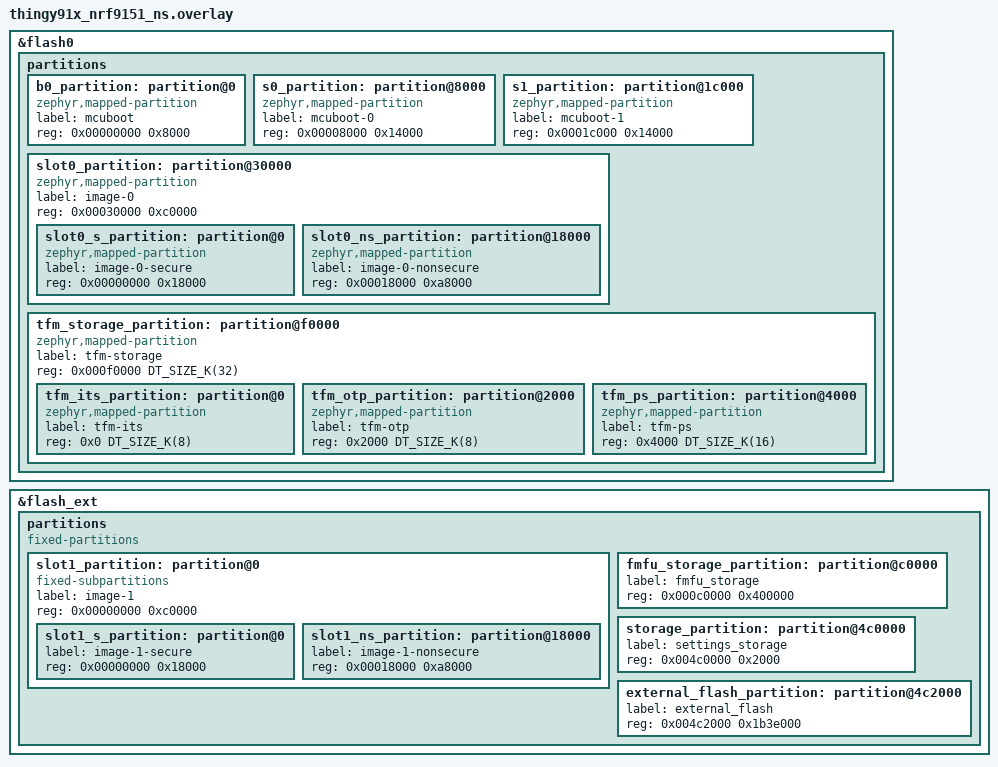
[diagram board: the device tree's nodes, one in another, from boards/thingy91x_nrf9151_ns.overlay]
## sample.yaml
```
sample:
  description: Cellular IoT Fundamentals Course by Nordic Developer Academy (https://academy.nordicsemi.com/)
  name: Cellular IoT Fundamentals Course - Lesson 5 Exercise 1 Solution
  
common: 
    sysbuild: true
    build_only: true
    integration_platforms: 
      - nrf9151dk/nrf9151/ns
      - nrf9161dk/nrf9161/ns
      - nrf9160dk/nrf9160/ns
      - thingy91x/nrf9151/ns
      - thingy91/nrf9160/ns
    platform_allow: 
      - nrf9151dk/nrf9151/ns
      - nrf9161dk/nrf9161/ns
      - nrf9160dk/nrf9160/ns
      - thingy91x/nrf9151/ns
      - thingy91/nrf9160/ns

tests:
  cell_fund.l5.e1_sol: {}
```

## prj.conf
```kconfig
#
# Copyright (c) 2019 Nordic Semiconductor ASA
#
# SPDX-License-Identifier: LicenseRef-Nordic-5-Clause
#

# Logging
CONFIG_LOG=y

# Button and LED support
CONFIG_DK_LIBRARY=y

# Newlib
CONFIG_NEWLIB_LIBC=y

# Network
CONFIG_NETWORKING=y
CONFIG_NET_NATIVE=n
CONFIG_NET_SOCKETS=y
CONFIG_NET_SOCKETS_OFFLOAD=y

# Memory
CONFIG_HEAP_MEM_POOL_SIZE=4096
CONFIG_MAIN_STACK_SIZE=4096

# Modem library
CONFIG_NRF_MODEM_LIB=y

# LTE link control
CONFIG_LTE_LINK_CONTROL=y
CONFIG_LTE_NETWORK_MODE_LTE_M_NBIOT=y

# CoAP
# STEP 2.1 - Enable the CoAP library
CONFIG_COAP=y

# STEP 3.1 - Configure the CoAP server hostname
CONFIG_COAP_SERVER_HOSTNAME="californium.eclipseprojects.io"

# STEP 3.2 - Configure the CoAP resource for TX and RX communication
CONFIG_COAP_TX_RESOURCE="large-update"
CONFIG_COAP_RX_RESOURCE="validate"

CONFIG_TFM_PROFILE_TYPE_SMALL=y
CONFIG_TFM_LOG_LEVEL_SILENCE=y
```

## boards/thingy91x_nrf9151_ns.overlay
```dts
/delete-node/ &slot0_partition;
/delete-node/ &slot1_partition;
/delete-node/ &s0_partition;
/delete-node/ &s1_partition;
/delete-node/ &storage_partition;
/delete-node/ &external_flash_partition;
/delete-node/ &fmfu_storage_partition;

&flash0 {
	/*
	 * 0x0000_0000  MCUboot (B0/NSIB)            ( 32 kB)
	 * 0x0000_8000  Primary updatable MCUboot    ( 80 kB)
	 * 0x0001_c000  Secondary updatable MCUboot  ( 80 kB)
	 * 0x0003_0000  Primary image area           (768 kB)
	 *   0x0003_0000  Primary secure image       ( 96 kB)
	 *   0x0004_8000  Primary non-secure image   (672 kB)
	 * 0x000f_0000  TF-M storage area            ( 32 kB)
	 *   0x000f_0000  TF-M Internal Trusted Stg  (  8 kB)
	 *   0x000f_2000  TF-M OTP / NV counters     (  8 kB)
	 *   0x000f_4000  TF-M Protected Storage     ( 16 kB)
	 * 0x000f_8000  Free                         ( 32 kB)
	 */
	partitions {
		ranges;
		#address-cells = <1>;
		#size-cells = <1>;

		b0_partition: partition@0 {
			compatible = "zephyr,mapped-partition";
			label = "mcuboot";
			reg = <0x00000000 0x8000>;
		};

		s0_partition: partition@8000 {
			compatible = "zephyr,mapped-partition";
			label = "mcuboot-0";
			reg = <0x00008000 0x14000>;
		};

		s1_partition: partition@1c000 {
			compatible = "zephyr,mapped-partition";
			label = "mcuboot-1";
			reg = <0x0001c000 0x14000>;
		};

		slot0_partition: partition@30000 {
			compatible = "zephyr,mapped-partition";
			label = "image-0";
			reg = <0x00030000 0xc0000>;
			ranges = <0x0 0x00030000 0xc0000>;
			#address-cells = <1>;
			#size-cells = <1>;

			slot0_s_partition: partition@0 {
				compatible = "zephyr,mapped-partition";
				label = "image-0-secure";
				reg = <0x00000000 0x18000>;
			};

			slot0_ns_partition: partition@18000 {
				compatible = "zephyr,mapped-partition";
				label = "image-0-nonsecure";
				reg = <0x00018000 0xa8000>;
			};
		};

		tfm_storage_partition: partition@f0000 {
			compatible = "zephyr,mapped-partition";
			label = "tfm-storage";
			reg = <0x000f0000 DT_SIZE_K(32)>;
			ranges = <0x0 0x000f0000 DT_SIZE_K(32)>;
			#address-cells = <1>;
			#size-cells = <1>;

			tfm_its_partition: partition@0 {
				compatible = "zephyr,mapped-partition";
				label = "tfm-its";
				reg = <0x0 DT_SIZE_K(8)>;
			};

			tfm_otp_partition: partition@2000 {
				compatible = "zephyr,mapped-partition";
				label = "tfm-otp";
				reg = <0x2000 DT_SIZE_K(8)>;
			};

			tfm_ps_partition: partition@4000 {
				compatible = "zephyr,mapped-partition";
				label = "tfm-ps";
				reg = <0x4000 DT_SIZE_K(16)>;
			};
		};
	};
};

&flash_ext {
	/*
	 * 0x0000_0000  Secondary image area          (  768 kB)
	 *   0x0000_0000  Secondary secure image      (   96 kB)
	 *   0x0001_8000  Secondary non-secure image  (  672 kB)
	 * 0x000c_0000  Full Modem Firmware Update    ( 4096 kB)
	 * 0x004c_0000  Settings                      (    8 kB)
	 * 0x004c_2000  Free                          (27896 kB)
	 */
	partitions {
		compatible = "fixed-partitions";
		#address-cells = <1>;
		#size-cells = <1>;

		slot1_partition: partition@0 {
			compatible = "fixed-subpartitions";
			label = "image-1";
			reg = <0x00000000 0xc0000>;
			ranges = <0x0 0x00000 0xc0000>;
			#address-cells = <1>;
			#size-cells = <1>;

			slot1_s_partition: partition@0 {
				label = "image-1-secure";
				reg = <0x00000000 0x18000>;
			};

			slot1_ns_partition: partition@18000 {
				label = "image-1-nonsecure";
				reg = <0x00018000 0xa8000>;
			};
		};

		fmfu_storage_partition: partition@c0000 {
			label = "fmfu_storage";
			reg = <0x000c0000 0x400000>;
		};

		storage_partition: partition@4c0000 {
			label = "settings_storage";
			reg = <0x004c0000 0x2000>;
		};

		external_flash_partition: partition@4c2000 {
			label = "external_flash";
			reg = <0x004c2000 0x1b3e000>;
		};
	};
};

/* Non-minimal TF-M profile needs the larger secure SRAM layout (88 kB). */
#include <samples/cellular/nrf91_sram_crypto_partitions.dtsi>
```

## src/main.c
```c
/*
 * Copyright (c) 2019 Nordic Semiconductor ASA
 *
 * SPDX-License-Identifier: LicenseRef-Nordic-5-Clause
 */

#include <stdio.h>
#include <ncs_version.h>

#include <zephyr/kernel.h>
#include <zephyr/net/socket.h>

#include <zephyr/logging/log.h>
#include <dk_buttons_and_leds.h>
#include <modem/nrf_modem_lib.h>
#include <modem/lte_lc.h>

#include <zephyr/random/random.h>

/* STEP 2.2 - Include the header file for the CoAP library */
#include <zephyr/net/coap.h>

/* STEP 4.1 - Define the macro for the message from the board */
#define MESSAGE_TO_SEND "Hi from nRF91 Series device"

/* STEP 4.2 - Define the macros for the CoAP version and message length */
#define APP_COAP_VERSION 1
#define APP_COAP_MAX_MSG_LEN 1280

/* STEP 5 - Declare the buffer coap_buf to receive the response. */
static uint8_t coap_buf[APP_COAP_MAX_MSG_LEN];

/* STEP 6.1 - Define the CoAP message token next_token */
static uint16_t next_token;

static int sock;
static struct sockaddr_storage server;

K_SEM_DEFINE(lte_connected, 0, 1);

LOG_MODULE_REGISTER(Lesson5_Exercise1, LOG_LEVEL_INF);

/**@brief Resolves the configured hostname. */
static int server_resolve(void)
{
	int err;
	struct addrinfo *result;
	struct addrinfo hints = {
		.ai_family = AF_INET,
		.ai_socktype = SOCK_DGRAM
	};
	char ipv4_addr[NET_IPV4_ADDR_LEN];

	err = getaddrinfo(CONFIG_COAP_SERVER_HOSTNAME, NULL, &hints, &result);
	if (err != 0) {
		LOG_ERR("ERROR: getaddrinfo failed %d\n", err);
		return -EIO;
	}

	if (result == NULL) {
		LOG_ERR("ERROR: Address not found\n");
		return -ENOENT;
	}

	/* IPv4 Address. */
	struct sockaddr_in *server4 = ((struct sockaddr_in *)&server);

	server4->sin_addr.s_addr =
		((struct sockaddr_in *)result->ai_addr)->sin_addr.s_addr;
	server4->sin_family = AF_INET;
	server4->sin_port = htons(CONFIG_COAP_SERVER_PORT);

	inet_ntop(AF_INET, &server4->sin_addr.s_addr, ipv4_addr,
		  sizeof(ipv4_addr));
	LOG_INF("IPv4 Address found %s\n", ipv4_addr);

	/* Free the address. */
	freeaddrinfo(result);

	return 0;
}

/**@brief Initialize the CoAP client */
static int client_init(void)
{
	int err;

	sock = socket(AF_INET, SOCK_DGRAM, IPPROTO_UDP);
	if (sock < 0) {
		LOG_ERR("Failed to create CoAP socket: %d.\n", errno);
		return -errno;
	}

	err = connect(sock, (struct sockaddr *)&server,
		      sizeof(struct sockaddr_in));
	if (err < 0) {
		LOG_ERR("Connect failed : %d\n", errno);
		return -errno;
	}

	LOG_INF("Successfully connected to server");

	/* STEP 6.2 - Generate a random token after the socket is connected */
	next_token = sys_rand32_get();

	return 0;
}

static void lte_handler(const struct lte_lc_evt *const evt)
{
     switch (evt->type) {
     case LTE_LC_EVT_NW_REG_STATUS:
        if ((evt->nw_reg_status != LTE_LC_NW_REG_REGISTERED_HOME) &&
            (evt->nw_reg_status != LTE_LC_NW_REG_REGISTERED_ROAMING)) {
            break;
        }
		LOG_INF("Network registration status: %s",
				evt->nw_reg_status == LTE_LC_NW_REG_REGISTERED_HOME ?
				"Connected - home network" : "Connected - roaming");
		k_sem_give(&lte_connected);
        break;
	case LTE_LC_EVT_RRC_UPDATE:
		LOG_INF("RRC mode: %s", evt->rrc_mode == LTE_LC_RRC_MODE_CONNECTED ?
				"Connected" : "Idle");
		break;
     default:
             break;
     }
}

static int modem_configure(void)
{
	int err;

	LOG_INF("Initializing modem library");
	err = nrf_modem_lib_init();
	if (err) {
		LOG_ERR("Failed to initialize the modem library, error: %d", err);
		return err;
	}

	
	LOG_INF("Connecting to LTE network");
	err = lte_lc_connect_async(lte_handler);
	if (err) {
		LOG_ERR("Error in lte_lc_connect_async, error: %d", err);
		return err;
	}

	k_sem_take(&lte_connected, K_FOREVER);
	LOG_INF("Connected to LTE network");
	dk_set_led_on(DK_LED2);

	return 0;
}

/**@biref Send CoAP GET request. */
static int client_get_send(void)
{
	/* STEP 7.1 - Create the CoAP message*/
	struct coap_packet request;

	next_token = sys_rand32_get();

	int err = coap_packet_init(&request, coap_buf, sizeof(coap_buf),
			       APP_COAP_VERSION, COAP_TYPE_NON_CON,
			       sizeof(next_token), (uint8_t *)&next_token,
			       COAP_METHOD_GET, coap_next_id());
	if (err < 0) {
		LOG_ERR("Failed to create CoAP request, %d\n", err);
		return err;
	}

	/* STEP 7.2 - Add an option specifying the resource path */
	err = coap_packet_append_option(&request, COAP_OPTION_URI_PATH,
					(uint8_t *)CONFIG_COAP_RX_RESOURCE,
					strlen(CONFIG_COAP_RX_RESOURCE));
	if (err < 0) {
		LOG_ERR("Failed to encode CoAP option, %d\n", err);
		return err;
	}

	/* STEP 7.3 - Send the configured CoAP packet */
	err = send(sock, request.data, request.offset, 0);
	if (err < 0) {
		LOG_ERR("Failed to send CoAP request, %d\n", errno);
		return -errno;
	}

	LOG_INF("CoAP GET request sent: Token 0x%04x\n", next_token);

	return 0;
}

/**@biref Send CoAP PUT request. */
static int client_put_send(void)
{
	int err;
	struct coap_packet request;

	next_token = sys_rand32_get();

	/* STEP 8.1 - Initialize the CoAP packet and append the resource path */
	err = coap_packet_init(&request, coap_buf, sizeof(coap_buf),
			       APP_COAP_VERSION, COAP_TYPE_NON_CON,
			       sizeof(next_token), (uint8_t *)&next_token,
			       COAP_METHOD_PUT, coap_next_id());
	if (err < 0) {
		LOG_ERR("Failed to create CoAP request, %d\n", err);
		return err;
	}

	err = coap_packet_append_option(&request, COAP_OPTION_URI_PATH,
					(uint8_t *)CONFIG_COAP_TX_RESOURCE,
					strlen(CONFIG_COAP_TX_RESOURCE));
	if (err < 0) {
		LOG_ERR("Failed to encode CoAP option, %d\n", err);
		return err;
	}

	/* STEP 8.2 - Append the content format as plain text */
	const uint8_t text_plain = COAP_CONTENT_FORMAT_TEXT_PLAIN;
	err = coap_packet_append_option(&request, COAP_OPTION_CONTENT_FORMAT,
					&text_plain,
					sizeof(text_plain));
	if (err < 0) {
		LOG_ERR("Failed to encode CoAP option, %d\n", err);
		return err;
	}

	/* STEP 8.3 - Add the payload to the message */
	err = coap_packet_append_payload_marker(&request);
	if (err < 0) {
		LOG_ERR("Failed to append payload marker, %d\n", err);
		return err;
	}

	err = coap_packet_append_payload(&request, (uint8_t *)MESSAGE_TO_SEND, sizeof(MESSAGE_TO_SEND));
	if (err < 0) {
		LOG_ERR("Failed to append payload, %d\n", err);
		return err;
	}

	err = send(sock, request.data, request.offset, 0);
	if (err < 0) {
		LOG_ERR("Failed to send CoAP request, %d\n", errno);
		return -errno;
	}

	LOG_INF("CoAP PUT request sent: Token 0x%04x\n", next_token);

	return 0;
}

/**@brief Handles responses from the remote CoAP server. */
static int client_handle_response(uint8_t *buf, int received)
{
	struct coap_packet reply;
	uint8_t token[8];
	uint16_t token_len;
	const uint8_t *payload;
	uint16_t payload_len;
	uint8_t temp_buf[128];
	/* STEP 9.1 - Parse the received CoAP packet */
	int err = coap_packet_parse(&reply, buf, received, NULL, 0);
	if (err < 0) {
		LOG_ERR("Malformed response received: %d\n", err);
		return err;
	}

	/* STEP 9.2 - Confirm the token in the response matches the token sent */
	token_len = coap_header_get_token(&reply, token);
	if ((token_len != sizeof(next_token)) ||
	    (memcmp(&next_token, token, sizeof(next_token)) != 0)) {
		LOG_ERR("Invalid token received: 0x%02x%02x\n",
		       token[1], token[0]);
		return 0;
	}

	/* STEP 9.3 - Retrieve the payload and confirm it's nonzero */
	payload = coap_packet_get_payload(&reply, &payload_len);

	if (payload_len > 0) {
		snprintf(temp_buf, MIN(payload_len + 1, sizeof(temp_buf)), "%s", payload);
	} else {
		strcpy(temp_buf, "EMPTY");
	}

	/* STEP 9.4 - Log the header code, token and payload of the response */
	LOG_INF("CoAP response: Code 0x%x, Token 0x%02x%02x, Payload: %s\n",
	       coap_header_get_code(&reply), token[1], token[0], (char *)temp_buf);

	return 0;
}

static void button_handler(uint32_t button_state, uint32_t has_changed)
{
	/* STEP 10 - Send a GET request or PUT request upon button triggers */
	#if defined (CONFIG_DK)
	if (has_changed & DK_BTN1_MSK && button_state & DK_BTN1_MSK) {
		client_get_send();
	} else if (has_changed & DK_BTN2_MSK && button_state & DK_BTN2_MSK) {
		client_put_send();
	}
	#elif defined (CONFIG_THINGY)
	static bool toogle = 1;
	if (has_changed & DK_BTN1_MSK && button_state & DK_BTN1_MSK) {
		if (toogle == 1) {
			client_get_send();
		} else {
			client_put_send();
		}
		toogle = !toogle;
	}
	#endif
}

int main(void)
{
	int err;
	int received;

	if (dk_leds_init() != 0) {
		LOG_ERR("Failed to initialize the LED library");
	}

	err = modem_configure();
	if (err) {
		LOG_ERR("Failed to configure the modem");
		return 0;
	}

	if (dk_buttons_init(button_handler) != 0) {
		LOG_ERR("Failed to initialize the buttons library");
	}

	if (server_resolve() != 0) {
		LOG_INF("Failed to resolve server name");
		return 0;
	}

	if (client_init() != 0) {
		LOG_INF("Failed to initialize client");
		return 0;
	}

	while (1) {
		/* STEP 11 - Receive response from the CoAP server */
		received = recv(sock, coap_buf, sizeof(coap_buf), 0);

		if (received < 0) {
			LOG_ERR("Socket error: %d, exit\n", errno);
			break;
		} else if (received == 0) {
			LOG_INF("Empty datagram\n");
			continue;
		}

		/* STEP 12 - Parse the received CoAP packet */
		err = client_handle_response(coap_buf, received);
		if (err < 0) {
			LOG_ERR("Invalid response, exit\n");
			break;
		}
	}

	(void)close(sock);

	return 0;
}
```
